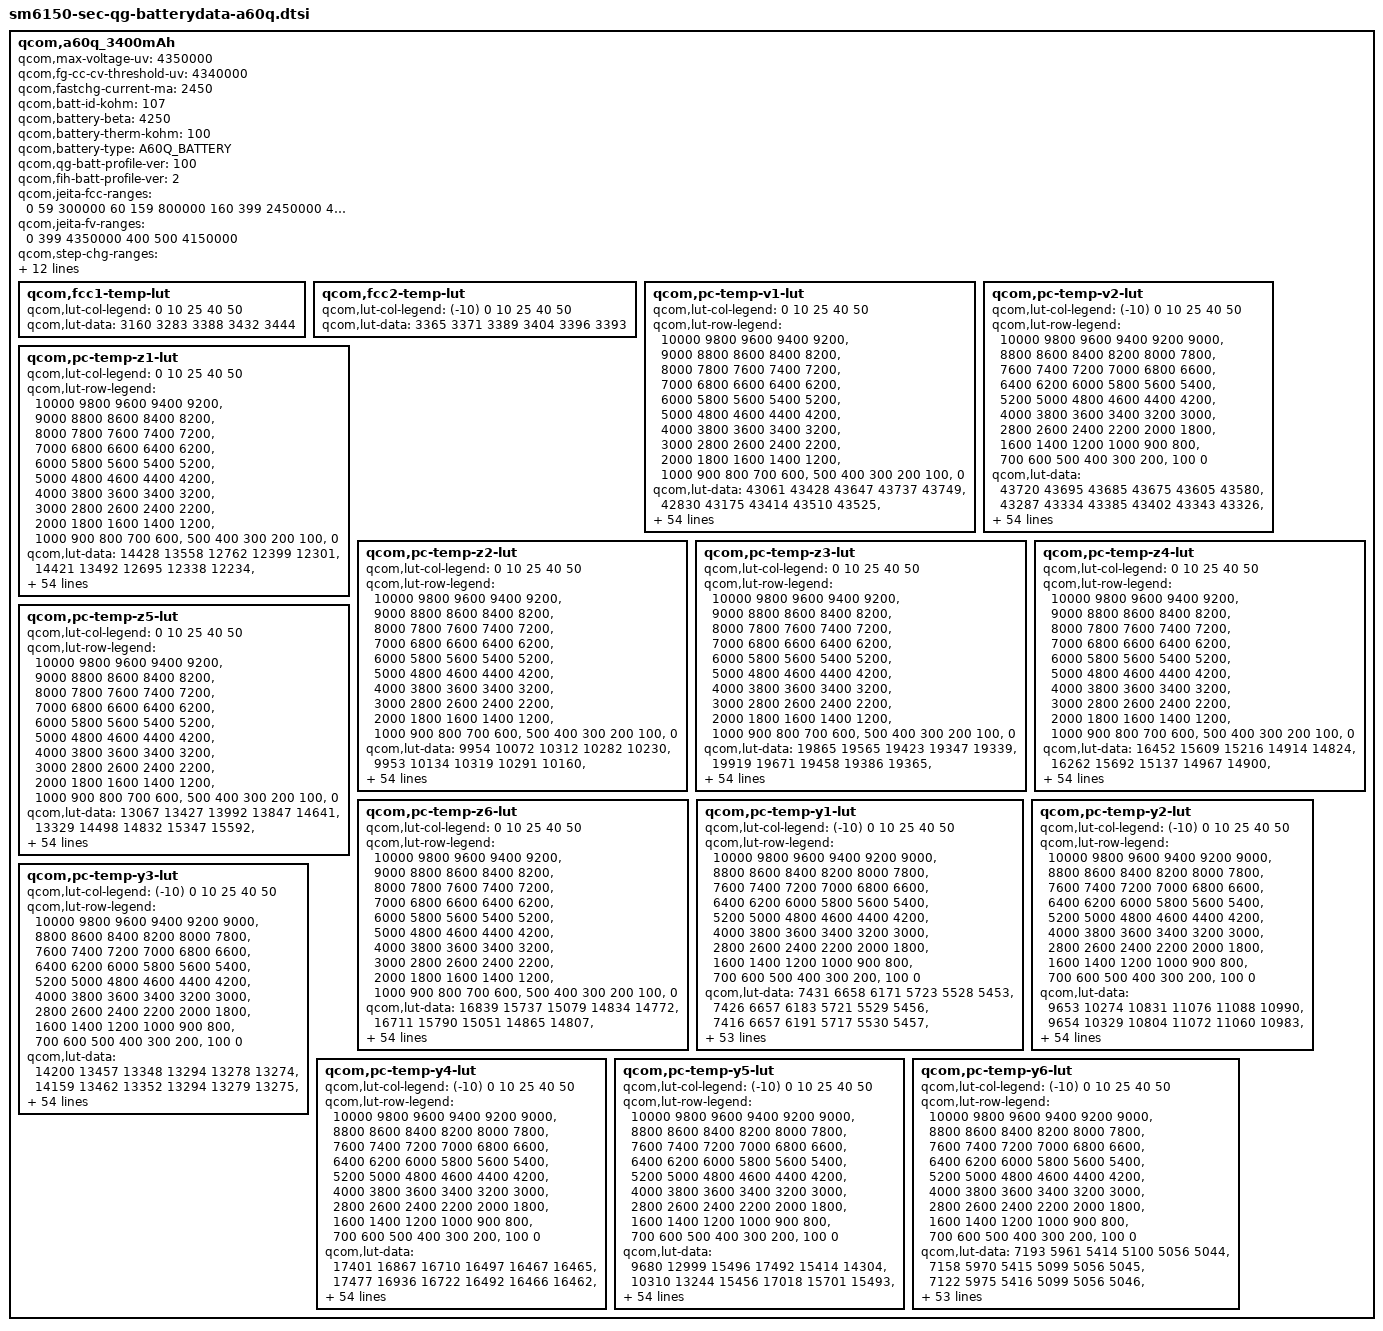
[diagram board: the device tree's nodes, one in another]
/*
 * Copyright (c) 2018, The Linux Foundation. All rights reserved.
 *
 * This program is free software; you can redistribute it and/or modify
 * it under the terms of the GNU General Public License version 2 and
 * only version 2 as published by the Free Software Foundation.
 *
 * This program is distributed in the hope that it will be useful,
 * but WITHOUT ANY WARRANTY; without even the implied warranty of
 * MERCHANTABILITY or FITNESS FOR A PARTICULAR PURPOSE.  See the
 * GNU General Public License for more details.
 */

qcom,a60q_3400mAh {
	 /* 3847662_SS_A60CHN_3400mAh_averaged_MasterSlave_Feb14th2019 */
	qcom,max-voltage-uv = <4350000>;
	qcom,fg-cc-cv-threshold-uv = <4340000>;
	qcom,fastchg-current-ma = <2450>;
	qcom,batt-id-kohm = <107>;
	qcom,battery-beta = <4250>;
	qcom,battery-therm-kohm = <100>;
	qcom,battery-type = "A60Q_BATTERY";
	qcom,qg-batt-profile-ver = <100>;
	qcom,fih-batt-profile-ver = <2>;

	qcom,jeita-fcc-ranges = <0  59   300000
				60  159  800000
				160 399  2450000
				400 490  1200000>;

	qcom,jeita-fv-ranges = <0   399  4350000
				400 500  4150000>;

	qcom,step-chg-ranges = <3400000  4089999  2450000
				4090000  4189999  2450000
				4190000  4350000  2450000>;
	qcom,vbat-avg-based-step-chg;
	qcom,taper-fcc;

	/* COOL = 15 DegC, WARM = 41 DegC */
	qcom,jeita-soft-thresholds = <0x45cd 0x2536>;
	/* COLD = 0 DegC, HOT = 50 DegC */
	qcom,jeita-hard-thresholds = <0x583d 0x1be6>;

	qcom,qg-batt-aging-enable;
	qcom,vfloat-ranges = <0 299 4350000
				300 399 4330000
				400 699 4310000
				700 999 4290000
				1000 9999 4240000>;

	qcom,vbat-rechg-ranges = <0 299 4280000
				300 399 4260000
				400 699 4240000
				700 999 4220000
				1000 9999 4170000>;

	qcom,full-condition-soc-ranges = <0 299 93
				300 399 92
				400 699 91
				700 999 90
				1000 9999 89>;

	qcom,fcc1-temp-lut {
		qcom,lut-col-legend = <0 10 25 40 50>;
		qcom,lut-data = <3160 3283 3388 3432 3444>;
	};

	qcom,fcc2-temp-lut {
		qcom,lut-col-legend = <(-10) 0 10 25 40 50>;
		qcom,lut-data = <3365 3371 3389 3404 3396 3393>;
	};

	qcom,pc-temp-v1-lut {
		qcom,lut-col-legend = <0 10 25 40 50>;
		qcom,lut-row-legend = <10000 9800 9600 9400 9200>,
			<9000 8800 8600 8400 8200>,
			<8000 7800 7600 7400 7200>,
			<7000 6800 6600 6400 6200>,
			<6000 5800 5600 5400 5200>,
			<5000 4800 4600 4400 4200>,
			<4000 3800 3600 3400 3200>,
			<3000 2800 2600 2400 2200>,
			<2000 1800 1600 1400 1200>,
			<1000 900 800 700 600>,
			<500 400 300 200 100>,
			<0>;
		qcom,lut-data = <43061 43428 43647 43737 43749>,
			<42830 43175 43414 43510 43525>,
			<42603 42940 43180 43281 43300>,
			<42379 42713 42944 43050 43076>,
			<42161 42485 42708 42819 42846>,
			<41950 42259 42473 42585 42612>,
			<41745 42036 42242 42353 42381>,
			<41546 41818 42014 42122 42153>,
			<41356 41604 41789 41894 41927>,
			<41171 41397 41565 41668 41700>,
			<40979 41200 41347 41444 41474>,
			<40776 41007 41134 41225 41255>,
			<40572 40808 40927 41010 41041>,
			<40371 40609 40725 40804 40833>,
			<40168 40416 40525 40603 40630>,
			<39990 40228 40336 40410 40434>,
			<39851 40051 40161 40227 40246>,
			<39730 39900 39995 40051 40068>,
			<39608 39771 39838 39883 39897>,
			<39485 39632 39694 39730 39740>,
			<39363 39469 39525 39572 39582>,
			<39243 39292 39269 39362 39384>,
			<39125 39100 39002 39108 39141>,
			<39004 38872 38842 38914 38940>,
			<38870 38691 38734 38783 38799>,
			<38733 38602 38640 38673 38680>,
			<38621 38541 38547 38565 38567>,
			<38531 38486 38461 38464 38464>,
			<38457 38437 38382 38373 38371>,
			<38401 38392 38306 38289 38286>,
			<38359 38346 38240 38214 38210>,
			<38324 38303 38179 38146 38139>,
			<38296 38260 38126 38087 38073>,
			<38272 38221 38079 38032 38012>,
			<38247 38183 38040 37985 37959>,
			<38218 38147 38000 37938 37906>,
			<38184 38116 37963 37888 37844>,
			<38142 38076 37923 37836 37777>,
			<38082 38007 37863 37769 37700>,
			<38007 37908 37775 37682 37611>,
			<37910 37801 37674 37581 37511>,
			<37780 37678 37562 37470 37399>,
			<37633 37537 37433 37342 37270>,
			<37467 37372 37272 37184 37114>,
			<37320 37231 37132 37045 36982>,
			<37220 37141 37045 36963 36902>,
			<37184 37115 37026 36940 36879>,
			<37156 37095 37006 36923 36865>,
			<37125 37075 36985 36905 36844>,
			<37040 37005 36929 36838 36764>,
			<36777 36744 36660 36545 36454>,
			<36319 36294 36218 36102 36009>,
			<35743 35716 35643 35524 35430>,
			<34964 34932 34859 34740 34644>,
			<33706 33677 33623 33504 33402>,
			<30000 30000 30000 30000 30000>;
	};

	qcom,pc-temp-v2-lut {
		qcom,lut-col-legend = <(-10) 0 10 25 40 50>;
		qcom,lut-row-legend = <10000 9800 9600 9400 9200 9000>,
			<8800 8600 8400 8200 8000 7800>,
			<7600 7400 7200 7000 6800 6600>,
			<6400 6200 6000 5800 5600 5400>,
			<5200 5000 4800 4600 4400 4200>,
			<4000 3800 3600 3400 3200 3000>,
			<2800 2600 2400 2200 2000 1800>,
			<1600 1400 1200 1000 900 800>,
			<700 600 500 400 300 200>,
			<100 0>;
		qcom,lut-data = <43720 43695 43685 43675 43605 43580>,
			<43287 43334 43385 43402 43343 43326>,
			<42898 43006 43103 43140 43090 43078>,
			<42558 42716 42839 42890 42846 42838>,
			<42260 42462 42594 42653 42612 42606>,
			<41984 42219 42356 42419 42380 42376>,
			<41693 41979 42120 42185 42149 42146>,
			<41425 41744 41888 41954 41920 41916>,
			<41266 41506 41662 41727 41695 41691>,
			<41184 41257 41439 41503 41472 41469>,
			<41080 41037 41223 41283 41254 41251>,
			<40778 40877 41019 41068 41039 41037>,
			<40317 40739 40821 40856 40829 40828>,
			<39999 40548 40615 40653 40628 40626>,
			<39795 40273 40396 40453 40431 40429>,
			<39610 39998 40190 40262 40243 40239>,
			<39407 39788 40012 40081 40063 40060>,
			<39206 39601 39844 39907 39889 39887>,
			<39017 39403 39649 39739 39722 39720>,
			<38832 39187 39422 39583 39567 39563>,
			<38669 38979 39201 39408 39395 39391>,
			<38538 38792 39002 39173 39166 39166>,
			<38425 38621 38819 38925 38921 38926>,
			<38334 38469 38666 38746 38744 38749>,
			<38260 38331 38536 38608 38610 38615>,
			<38196 38218 38419 38489 38494 38499>,
			<38137 38141 38309 38385 38388 38392>,
			<38082 38081 38207 38292 38292 38295>,
			<38028 38027 38117 38206 38205 38205>,
			<37976 37979 38035 38126 38125 38121>,
			<37924 37934 37965 38052 38053 38046>,
			<37872 37889 37904 37982 37986 37980>,
			<37820 37846 37851 37917 37924 37918>,
			<37766 37800 37807 37855 37859 37851>,
			<37711 37754 37773 37798 37794 37779>,
			<37653 37704 37736 37739 37721 37697>,
			<37591 37647 37691 37673 37628 37591>,
			<37527 37585 37638 37604 37525 37473>,
			<37456 37514 37577 37532 37437 37376>,
			<37375 37431 37507 37457 37363 37299>,
			<37288 37340 37423 37375 37284 37219>,
			<37202 37239 37310 37280 37187 37121>,
			<37117 37127 37174 37171 37074 37008>,
			<37031 37006 37030 37030 36930 36864>,
			<36944 36879 36901 36909 36831 36772>,
			<36850 36765 36819 36855 36793 36737>,
			<36795 36718 36789 36844 36779 36722>,
			<36737 36668 36774 36825 36762 36707>,
			<36662 36614 36738 36796 36728 36674>,
			<36552 36518 36651 36724 36632 36545>,
			<36340 36329 36385 36467 36307 36198>,
			<35966 35912 35899 35990 35821 35704>,
			<35399 35302 35249 35372 35186 35059>,
			<34575 34470 34367 34546 34321 34172>,
			<33218 33139 33060 33268 33044 32883>,
			<30242 27893 27843 27859 27886 27882>;
	};

	qcom,pc-temp-z1-lut {
		qcom,lut-col-legend = <0 10 25 40 50>;
		qcom,lut-row-legend = <10000 9800 9600 9400 9200>,
			<9000 8800 8600 8400 8200>,
			<8000 7800 7600 7400 7200>,
			<7000 6800 6600 6400 6200>,
			<6000 5800 5600 5400 5200>,
			<5000 4800 4600 4400 4200>,
			<4000 3800 3600 3400 3200>,
			<3000 2800 2600 2400 2200>,
			<2000 1800 1600 1400 1200>,
			<1000 900 800 700 600>,
			<500 400 300 200 100>,
			<0>;
		qcom,lut-data = <14428 13558 12762 12399 12301>,
			<14421 13492 12695 12338 12234>,
			<14412 13456 12645 12305 12209>,
			<14374 13430 12618 12285 12194>,
			<14333 13407 12601 12272 12184>,
			<14312 13386 12587 12264 12177>,
			<14283 13373 12572 12259 12175>,
			<14265 13366 12561 12256 12174>,
			<14262 13360 12559 12254 12174>,
			<14263 13352 12558 12253 12174>,
			<14257 13333 12558 12252 12174>,
			<14238 13317 12558 12252 12174>,
			<14212 13314 12558 12252 12175>,
			<14189 13316 12557 12253 12175>,
			<14166 13318 12555 12254 12177>,
			<14151 13312 12554 12255 12179>,
			<14142 13305 12556 12257 12180>,
			<14133 13306 12561 12259 12182>,
			<14131 13314 12566 12261 12183>,
			<14136 13322 12576 12264 12186>,
			<14143 13330 12584 12267 12189>,
			<14149 13338 12587 12271 12191>,
			<14155 13341 12590 12275 12194>,
			<14161 13338 12594 12279 12196>,
			<14171 13336 12599 12285 12201>,
			<14183 13338 12604 12291 12206>,
			<14189 13340 12611 12295 12210>,
			<14186 13344 12618 12300 12214>,
			<14181 13361 12624 12304 12219>,
			<14181 13377 12632 12309 12223>,
			<14184 13376 12639 12313 12227>,
			<14187 13366 12646 12318 12230>,
			<14199 13362 12652 12322 12233>,
			<14220 13366 12656 12327 12237>,
			<14232 13372 12658 12332 12240>,
			<14229 13379 12661 12336 12244>,
			<14225 13392 12667 12341 12248>,
			<14227 13401 12674 12346 12252>,
			<14237 13405 12681 12350 12255>,
			<14247 13408 12686 12355 12259>,
			<14252 13411 12692 12360 12262>,
			<14254 13414 12699 12365 12267>,
			<14265 13422 12706 12370 12272>,
			<14284 13443 12711 12375 12275>,
			<14256 13456 12724 12381 12277>,
			<14259 13442 12725 12387 12280>,
			<14258 13454 12739 12389 12282>,
			<14254 13436 12731 12390 12283>,
			<14257 13450 12735 12394 12287>,
			<14275 13465 12754 12401 12291>,
			<14294 13465 12753 12410 12300>,
			<14301 13482 12767 12424 12311>,
			<14334 13529 12797 12440 12326>,
			<14390 13555 12820 12467 12346>,
			<14390 13555 12820 12467 12346>,
			<14390 13555 12820 12467 12346>;
	};

	qcom,pc-temp-z2-lut {
		qcom,lut-col-legend = <0 10 25 40 50>;
		qcom,lut-row-legend = <10000 9800 9600 9400 9200>,
			<9000 8800 8600 8400 8200>,
			<8000 7800 7600 7400 7200>,
			<7000 6800 6600 6400 6200>,
			<6000 5800 5600 5400 5200>,
			<5000 4800 4600 4400 4200>,
			<4000 3800 3600 3400 3200>,
			<3000 2800 2600 2400 2200>,
			<2000 1800 1600 1400 1200>,
			<1000 900 800 700 600>,
			<500 400 300 200 100>,
			<0>;
		qcom,lut-data = <9954 10072 10312 10282 10230>,
			<9953 10134 10319 10291 10160>,
			<9956 10115 10318 10349 10158>,
			<9970 10083 10309 10380 10158>,
			<9984 10057 10282 10355 10192>,
			<9989 10030 10256 10316 10261>,
			<9992 10010 10229 10286 10269>,
			<9994 9996 10209 10237 10179>,
			<9987 9987 10214 10208 10110>,
			<9972 9985 10240 10205 10115>,
			<9955 9994 10256 10206 10128>,
			<9934 10007 10259 10212 10134>,
			<9912 10020 10259 10218 10135>,
			<9897 10035 10264 10223 10138>,
			<9884 10049 10279 10218 10154>,
			<9877 10063 10288 10212 10176>,
			<9883 10077 10289 10217 10190>,
			<9896 10089 10292 10226 10200>,
			<9902 10100 10296 10232 10212>,
			<9904 10111 10303 10240 10235>,
			<9905 10127 10307 10252 10260>,
			<9908 10142 10294 10262 10275>,
			<9914 10142 10270 10269 10286>,
			<9921 10119 10247 10271 10293>,
			<9932 10101 10221 10287 10297>,
			<9946 10106 10210 10307 10294>,
			<9956 10120 10273 10309 10258>,
			<9961 10130 10356 10306 10169>,
			<9966 10137 10359 10298 10120>,
			<9973 10143 10319 10274 10108>,
			<9985 10147 10293 10243 10101>,
			<9996 10152 10286 10205 10105>,
			<10001 10157 10283 10163 10121>,
			<10004 10164 10290 10155 10142>,
			<10009 10173 10318 10190 10179>,
			<10021 10181 10345 10234 10224>,
			<10035 10187 10361 10262 10266>,
			<10038 10195 10377 10287 10309>,
			<10011 10210 10398 10320 10339>,
			<9989 10227 10431 10369 10364>,
			<10008 10231 10449 10399 10377>,
			<10073 10227 10450 10401 10372>,
			<10540 10226 10452 10401 10362>,
			<12169 10235 10458 10404 10364>,
			<14641 10334 10471 10408 10373>,
			<16171 10363 10490 10444 10394>,
			<16365 10391 10478 10440 10355>,
			<16147 14850 10451 10429 10401>,
			<16310 27487 10482 10466 10460>,
			<16343 12036 10545 10655 10538>,
			<14691 20046 10736 10386 10237>,
			<12946 19041 10620 10287 10156>,
			<10998 18325 10639 10251 10121>,
			<10233 10418 10501 10304 10122>,
			<10233 10418 10501 10304 10122>,
			<10233 10418 10501 10304 10122>;
	};

	qcom,pc-temp-z3-lut {
		qcom,lut-col-legend = <0 10 25 40 50>;
		qcom,lut-row-legend = <10000 9800 9600 9400 9200>,
			<9000 8800 8600 8400 8200>,
			<8000 7800 7600 7400 7200>,
			<7000 6800 6600 6400 6200>,
			<6000 5800 5600 5400 5200>,
			<5000 4800 4600 4400 4200>,
			<4000 3800 3600 3400 3200>,
			<3000 2800 2600 2400 2200>,
			<2000 1800 1600 1400 1200>,
			<1000 900 800 700 600>,
			<500 400 300 200 100>,
			<0>;
		qcom,lut-data = <19865 19565 19423 19347 19339>,
			<19919 19671 19458 19386 19365>,
			<19933 19693 19483 19407 19377>,
			<19932 19704 19495 19417 19386>,
			<19930 19707 19504 19423 19397>,
			<19917 19706 19507 19426 19407>,
			<19878 19705 19501 19425 19407>,
			<19852 19701 19491 19417 19396>,
			<19845 19696 19482 19410 19385>,
			<19841 19688 19472 19404 19382>,
			<19841 19672 19463 19398 19380>,
			<19846 19655 19455 19394 19377>,
			<19852 19644 19449 19390 19371>,
			<19860 19634 19446 19386 19365>,
			<19874 19625 19443 19381 19363>,
			<19882 19617 19440 19375 19361>,
			<19859 19609 19431 19371 19359>,
			<19815 19597 19420 19369 19357>,
			<19795 19583 19418 19366 19355>,
			<19790 19576 19417 19364 19352>,
			<19788 19585 19417 19363 19349>,
			<19789 19599 19429 19362 19346>,
			<19793 19604 19445 19362 19342>,
			<19799 19605 19442 19362 19340>,
			<19810 19605 19421 19358 19353>,
			<19825 19604 19409 19356 19372>,
			<19830 19601 19416 19371 19381>,
			<19826 19598 19429 19400 19389>,
			<19819 19595 19441 19409 19391>,
			<19811 19592 19456 19407 19386>,
			<19803 19592 19463 19404 19377>,
			<19793 19593 19460 19399 19372>,
			<19782 19593 19454 19392 19368>,
			<19768 19592 19449 19385 19363>,
			<19755 19589 19443 19379 19355>,
			<19743 19585 19437 19373 19350>,
			<19730 19579 19433 19369 19349>,
			<19700 19573 19429 19366 19349>,
			<19583 19567 19425 19364 19349>,
			<19479 19561 19421 19363 19351>,
			<19410 19556 19418 19362 19352>,
			<19283 19551 19414 19360 19351>,
			<19261 19544 19411 19358 19348>,
			<19258 19531 19407 19357 19351>,
			<19257 19494 19396 19356 19348>,
			<19257 19480 19391 19345 19336>,
			<19257 19459 19370 19343 19335>,
			<19257 19399 19376 19342 19323>,
			<19257 19267 19371 19328 19318>,
			<19257 19338 19360 19318 19316>,
			<19257 19340 19341 19356 19353>,
			<19257 19310 19353 19358 19356>,
			<19259 19308 19344 19363 19359>,
			<19261 19348 19356 19340 19349>,
			<19261 19348 19356 19340 19349>,
			<19261 19348 19356 19340 19349>;
	};

	qcom,pc-temp-z4-lut {
		qcom,lut-col-legend = <0 10 25 40 50>;
		qcom,lut-row-legend = <10000 9800 9600 9400 9200>,
			<9000 8800 8600 8400 8200>,
			<8000 7800 7600 7400 7200>,
			<7000 6800 6600 6400 6200>,
			<6000 5800 5600 5400 5200>,
			<5000 4800 4600 4400 4200>,
			<4000 3800 3600 3400 3200>,
			<3000 2800 2600 2400 2200>,
			<2000 1800 1600 1400 1200>,
			<1000 900 800 700 600>,
			<500 400 300 200 100>,
			<0>;
		qcom,lut-data = <16452 15609 15216 14914 14824>,
			<16262 15692 15137 14967 14900>,
			<16075 15551 15065 14933 14883>,
			<15880 15338 14999 14894 14859>,
			<15709 15207 14938 14861 14832>,
			<15590 15112 14889 14830 14801>,
			<15498 15036 14851 14805 14781>,
			<15415 14975 14821 14784 14769>,
			<15335 14925 14801 14769 14759>,
			<15261 14885 14785 14759 14749>,
			<15191 14851 14773 14751 14740>,
			<15122 14826 14764 14741 14732>,
			<15061 14810 14755 14731 14726>,
			<15011 14799 14746 14723 14719>,
			<14966 14792 14735 14716 14710>,
			<14933 14790 14727 14709 14700>,
			<14915 14787 14722 14701 14691>,
			<14902 14780 14717 14692 14682>,
			<14887 14765 14711 14686 14677>,
			<14868 14757 14703 14681 14674>,
			<14850 14763 14700 14679 14673>,
			<14838 14780 14777 14715 14698>,
			<14827 14815 14884 14825 14799>,
			<14822 14917 14907 14871 14850>,
			<14831 14992 14910 14866 14830>,
			<14853 14981 14905 14854 14796>,
			<14869 14949 14880 14826 14770>,
			<14880 14919 14840 14773 14745>,
			<14888 14892 14806 14742 14727>,
			<14888 14865 14772 14726 14716>,
			<14875 14842 14749 14715 14708>,
			<14859 14819 14738 14707 14699>,
			<14845 14803 14731 14701 14691>,
			<14830 14792 14727 14699 14687>,
			<14817 14783 14724 14698 14686>,
			<14804 14774 14722 14698 14686>,
			<14794 14764 14723 14701 14690>,
			<14805 14759 14724 14708 14701>,
			<14912 14762 14728 14715 14707>,
			<15008 14765 14738 14723 14710>,
			<15070 14765 14744 14728 14711>,
			<15196 14751 14733 14721 14707>,
			<15208 14742 14722 14712 14700>,
			<15186 14739 14722 14716 14704>,
			<15075 14716 14712 14708 14701>,
			<15065 14703 14690 14694 14684>,
			<15060 14708 14691 14679 14671>,
			<15051 14760 14666 14659 14660>,
			<15038 14899 14657 14651 14643>,
			<15030 14818 14672 14666 14649>,
			<15036 14824 14720 14660 14649>,
			<15063 14874 14712 14662 14650>,
			<15080 14884 14726 14660 14650>,
			<15097 14855 14716 14686 14660>,
			<15097 14855 14716 14686 14660>,
			<15097 14855 14716 14686 14660>;
	};

	qcom,pc-temp-z5-lut {
		qcom,lut-col-legend = <0 10 25 40 50>;
		qcom,lut-row-legend = <10000 9800 9600 9400 9200>,
			<9000 8800 8600 8400 8200>,
			<8000 7800 7600 7400 7200>,
			<7000 6800 6600 6400 6200>,
			<6000 5800 5600 5400 5200>,
			<5000 4800 4600 4400 4200>,
			<4000 3800 3600 3400 3200>,
			<3000 2800 2600 2400 2200>,
			<2000 1800 1600 1400 1200>,
			<1000 900 800 700 600>,
			<500 400 300 200 100>,
			<0>;
		qcom,lut-data = <13067 13427 13992 13847 14641>,
			<13329 14498 14832 15347 15592>,
			<13574 15086 15600 16387 16294>,
			<13857 15561 16316 17047 16947>,
			<14072 16130 17054 17524 18069>,
			<14105 16758 17480 17932 19289>,
			<14049 17407 17674 18197 19505>,
			<14033 18173 17863 18465 18902>,
			<14153 19022 18112 18544 18438>,
			<14382 19750 18439 18530 18725>,
			<14671 20546 18616 18568 19261>,
			<15090 21283 18666 18743 19359>,
			<15661 22107 18796 19235 19189>,
			<16641 23200 19258 19441 19074>,
			<18322 23682 20209 19342 19512>,
			<19311 23384 20674 19419 20456>,
			<18792 23009 20358 19923 21421>,
			<17804 23057 19945 20796 22562>,
			<17481 23176 20085 21699 23616>,
			<18119 23416 21158 22825 24644>,
			<19254 28360 22821 23683 25421>,
			<20583 35581 27600 23373 24554>,
			<22470 37063 32849 21939 20509>,
			<25012 36348 31590 20554 17765>,
			<30035 35305 23116 17480 16724>,
			<36817 33264 18193 14900 16096>,
			<39379 30046 17911 15527 16659>,
			<38823 28073 17879 17704 18450>,
			<37807 26923 18597 19656 19687>,
			<36688 26271 21327 21330 20164>,
			<35230 26616 24176 22864 20619>,
			<33563 28051 26568 24164 21593>,
			<31557 29768 28736 25330 23098>,
			<29202 32299 30325 26315 24104>,
			<27556 34683 31698 27339 24756>,
			<26385 35230 32263 27925 25119>,
			<25313 35377 32059 27439 25094>,
			<24137 35436 31580 26106 24949>,
			<20458 35019 30498 24661 24653>,
			<17201 34065 27687 22800 23551>,
			<15137 33181 25591 21341 22315>,
			<11475 32087 24993 20763 21522>,
			<10929 30409 24414 20289 20926>,
			<10949 27216 22947 19283 20599>,
			<11103 25680 22306 19418 19604>,
			<11073 24198 22849 18159 17942>,
			<11058 19660 18501 18745 18440>,
			<11027 15884 20796 20523 18040>,
			<11020 11272 20876 19051 19444>,
			<11066 12576 18099 16092 17522>,
			<11105 13785 14386 19344 22325>,
			<11066 12143 14736 18683 21663>,
			<11007 11857 13836 19079 21115>,
			<10940 12155 14331 14504 16923>,
			<10940 12155 14331 14504 16923>,
			<10940 12155 14331 14504 16923>;
	};

	qcom,pc-temp-z6-lut {
		qcom,lut-col-legend = <0 10 25 40 50>;
		qcom,lut-row-legend = <10000 9800 9600 9400 9200>,
			<9000 8800 8600 8400 8200>,
			<8000 7800 7600 7400 7200>,
			<7000 6800 6600 6400 6200>,
			<6000 5800 5600 5400 5200>,
			<5000 4800 4600 4400 4200>,
			<4000 3800 3600 3400 3200>,
			<3000 2800 2600 2400 2200>,
			<2000 1800 1600 1400 1200>,
			<1000 900 800 700 600>,
			<500 400 300 200 100>,
			<0>;
		qcom,lut-data = <16839 15737 15079 14834 14772>,
			<16711 15790 15051 14865 14807>,
			<16582 15712 15023 14855 14802>,
			<16447 15592 14997 14843 14796>,
			<16323 15512 14971 14831 14789>,
			<16222 15450 14947 14818 14781>,
			<16134 15397 14925 14805 14772>,
			<16060 15354 14905 14791 14760>,
			<16001 15318 14889 14780 14750>,
			<15949 15285 14876 14772 14744>,
			<15899 15254 14866 14765 14739>,
			<15846 15229 14857 14759 14733>,
			<15800 15210 14850 14752 14727>,
			<15768 15195 14843 14746 14721>,
			<15744 15185 14837 14740 14716>,
			<15722 15178 14832 14734 14711>,
			<15696 15173 14824 14729 14706>,
			<15671 15165 14818 14723 14701>,
			<15657 15155 14815 14720 14697>,
			<15649 15150 14812 14717 14695>,
			<15644 15157 14812 14716 14693>,
			<15644 15173 14853 14732 14703>,
			<15646 15197 14909 14781 14745>,
			<15649 15244 14916 14800 14767>,
			<15660 15276 14909 14797 14765>,
			<15681 15271 14903 14793 14763>,
			<15692 15258 14896 14788 14759>,
			<15695 15246 14889 14782 14753>,
			<15697 15235 14882 14776 14747>,
			<15696 15226 14877 14770 14739>,
			<15688 15217 14871 14764 14732>,
			<15678 15209 14866 14758 14726>,
			<15670 15204 14861 14752 14721>,
			<15661 15200 14857 14747 14716>,
			<15653 15197 14852 14743 14711>,
			<15646 15195 14850 14741 14709>,
			<15639 15192 14850 14741 14710>,
			<15636 15191 14850 14743 14714>,
			<15632 15193 14850 14744 14718>,
			<15630 15197 14854 14748 14721>,
			<15629 15198 14856 14751 14722>,
			<15628 15195 14852 14747 14720>,
			<15630 15194 14847 14743 14717>,
			<15633 15195 14847 14745 14720>,
			<15597 15179 14840 14743 14718>,
			<15599 15170 14829 14732 14705>,
			<15598 15164 14819 14725 14699>,
			<15597 15159 14812 14715 14689>,
			<15597 15156 14807 14705 14678>,
			<15600 15160 14810 14707 14680>,
			<15616 15175 14825 14727 14702>,
			<15643 15192 14831 14732 14707>,
			<15672 15208 14838 14738 14712>,
			<15713 15234 14848 14743 14716>,
			<15713 15234 14848 14743 14716>,
			<15713 15234 14848 14743 14716>;
	};

	qcom,pc-temp-y1-lut {
		qcom,lut-col-legend = <(-10) 0 10 25 40 50>;
		qcom,lut-row-legend = <10000 9800 9600 9400 9200 9000>,
			<8800 8600 8400 8200 8000 7800>,
			<7600 7400 7200 7000 6800 6600>,
			<6400 6200 6000 5800 5600 5400>,
			<5200 5000 4800 4600 4400 4200>,
			<4000 3800 3600 3400 3200 3000>,
			<2800 2600 2400 2200 2000 1800>,
			<1600 1400 1200 1000 900 800>,
			<700 600 500 400 300 200>,
			<100 0>;
		qcom,lut-data = <7431 6658 6171 5723 5528 5453>,
			<7426 6657 6183 5721 5529 5456>,
			<7416 6657 6191 5717 5530 5457>,
			<7406 6657 6195 5714 5530 5458>,
			<7397 6657 6196 5710 5529 5459>,
			<7392 6658 6196 5709 5528 5459>,
			<7391 6665 6193 5708 5525 5459>,
			<7391 6677 6187 5706 5522 5458>,
			<7392 6679 6186 5706 5521 5457>,
			<7400 6672 6185 5703 5520 5456>,
			<7409 6667 6185 5702 5520 5456>,
			<7416 6671 6187 5702 5520 5456>,
			<7422 6679 6191 5703 5521 5457>,
			<7423 6688 6191 5703 5521 5457>,
			<7422 6703 6186 5702 5521 5457>,
			<7419 6714 6182 5701 5522 5458>,
			<7412 6710 6186 5702 5523 5460>,
			<7400 6702 6193 5703 5524 5463>,
			<7397 6701 6196 5704 5526 5464>,
			<7407 6714 6197 5706 5529 5464>,
			<7415 6726 6199 5709 5531 5464>,
			<7411 6726 6201 5711 5531 5466>,
			<7399 6720 6203 5715 5531 5468>,
			<7395 6716 6203 5717 5532 5470>,
			<7405 6703 6199 5720 5535 5471>,
			<7416 6691 6196 5723 5539 5472>,
			<7415 6694 6198 5727 5541 5474>,
			<7410 6703 6200 5732 5543 5477>,
			<7408 6706 6203 5736 5545 5479>,
			<7408 6701 6207 5740 5548 5481>,
			<7408 6695 6210 5744 5550 5483>,
			<7404 6699 6214 5750 5553 5486>,
			<7392 6708 6220 5756 5556 5489>,
			<7387 6712 6222 5759 5558 5492>,
			<7397 6707 6220 5762 5561 5494>,
			<7409 6701 6220 5764 5564 5495>,
			<7410 6703 6221 5770 5568 5497>,
			<7408 6711 6223 5776 5572 5498>,
			<7405 6715 6227 5779 5575 5500>,
			<7410 6710 6236 5780 5577 5504>,
			<7417 6705 6248 5783 5579 5508>,
			<7416 6704 6258 5786 5581 5508>,
			<7411 6703 6266 5790 5583 5509>,
			<7405 6705 6254 5794 5585 5512>,
			<7395 6715 6254 5802 5588 5515>,
			<7422 6735 6264 5804 5594 5519>,
			<7428 6743 6263 5807 5593 5519>,
			<7431 6777 6256 5806 5594 5519>,
			<7432 6768 6271 5807 5595 5520>,
			<7423 6743 6263 5811 5596 5522>,
			<7456 6767 6271 5817 5600 5526>,
			<7451 6769 6295 5823 5609 5534>,
			<7489 6795 6327 5841 5622 5544>,
			<7520 6834 6334 5866 5638 5558>,
			<7520 6834 6334 5866 5638 5558>,
			<7520 6834 6334 5866 5638 5558>;
	};

	qcom,pc-temp-y2-lut {
		qcom,lut-col-legend = <(-10) 0 10 25 40 50>;
		qcom,lut-row-legend = <10000 9800 9600 9400 9200 9000>,
			<8800 8600 8400 8200 8000 7800>,
			<7600 7400 7200 7000 6800 6600>,
			<6400 6200 6000 5800 5600 5400>,
			<5200 5000 4800 4600 4400 4200>,
			<4000 3800 3600 3400 3200 3000>,
			<2800 2600 2400 2200 2000 1800>,
			<1600 1400 1200 1000 900 800>,
			<700 600 500 400 300 200>,
			<100 0>;
		qcom,lut-data = <9653 10274 10831 11076 11088 10990>,
			<9654 10329 10804 11072 11060 10983>,
			<9655 10374 10778 11058 11019 10963>,
			<9656 10407 10754 11037 10976 10936>,
			<9656 10428 10731 11014 10940 10911>,
			<9657 10436 10711 10993 10919 10894>,
			<9658 10424 10691 10967 10912 10879>,
			<9658 10403 10674 10940 10907 10861>,
			<9659 10409 10667 10930 10901 10850>,
			<9660 10483 10665 10916 10893 10835>,
			<9660 10539 10664 10908 10889 10826>,
			<9660 10526 10669 10913 10887 10834>,
			<9659 10501 10679 10921 10881 10849>,
			<9658 10502 10697 10918 10871 10852>,
			<9658 10556 10740 10902 10858 10849>,
			<9658 10600 10779 10895 10847 10841>,
			<9658 10603 10806 10915 10842 10823>,
			<9658 10604 10829 10951 10843 10803>,
			<9658 10605 10829 11001 10873 10813>,
			<9657 10607 10808 11079 10997 10896>,
			<9657 10612 10792 11119 11085 10959>,
			<9657 10620 10800 11080 11080 10957>,
			<9657 10632 10819 11022 11057 10945>,
			<9656 10603 10839 11017 11049 10955>,
			<9656 10229 10867 11043 11032 10977>,
			<9656 9865 10892 11073 11020 11002>,
			<9656 9812 10907 11107 11055 11027>,
			<9655 9789 10920 11139 11114 11053>,
			<9655 9773 10929 11153 11133 11076>,
			<9654 9748 10938 11161 11130 11103>,
			<9654 9722 10943 11165 11126 11122>,
			<9654 9703 10946 11165 11139 11127>,
			<9654 9686 10947 11162 11165 11130>,
			<9653 9677 10942 11161 11181 11138>,
			<9653 9672 10919 11161 11194 11155>,
			<9653 9669 10887 11161 11199 11168>,
			<9653 9665 10855 11159 11177 11166>,
			<9653 9662 10817 11158 11141 11157>,
			<9653 9660 10772 11164 11134 11144>,
			<9653 9659 10715 11176 11138 11109>,
			<9653 9657 10644 11184 11141 11082>,
			<9653 9656 10423 11178 11146 11072>,
			<9653 9655 10149 11167 11154 11067>,
			<9653 9654 10177 11146 11160 11111>,
			<9652 9654 10153 11103 11128 11096>,
			<9652 9653 10002 11102 11067 10951>,
			<9652 9653 9979 11030 11029 10878>,
			<9652 9653 10207 11080 10996 10853>,
			<9652 9653 10259 11075 10984 10835>,
			<9652 9653 10245 11009 10972 10860>,
			<9652 9652 9962 10995 10952 10833>,
			<9652 9652 9758 10943 10907 10760>,
			<9651 9651 9692 10898 10822 10724>,
			<9651 9651 9671 10790 10694 10598>,
			<9651 9651 9671 10790 10694 10598>,
			<9651 9651 9671 10790 10694 10598>;
	};

	qcom,pc-temp-y3-lut {
		qcom,lut-col-legend = <(-10) 0 10 25 40 50>;
		qcom,lut-row-legend = <10000 9800 9600 9400 9200 9000>,
			<8800 8600 8400 8200 8000 7800>,
			<7600 7400 7200 7000 6800 6600>,
			<6400 6200 6000 5800 5600 5400>,
			<5200 5000 4800 4600 4400 4200>,
			<4000 3800 3600 3400 3200 3000>,
			<2800 2600 2400 2200 2000 1800>,
			<1600 1400 1200 1000 900 800>,
			<700 600 500 400 300 200>,
			<100 0>;
		qcom,lut-data = <14200 13457 13348 13294 13278 13274>,
			<14159 13462 13352 13294 13279 13275>,
			<14114 13471 13355 13295 13280 13277>,
			<14065 13480 13359 13295 13281 13278>,
			<14013 13488 13362 13295 13281 13279>,
			<13959 13492 13365 13295 13282 13280>,
			<13889 13494 13368 13295 13282 13279>,
			<13821 13494 13370 13295 13282 13279>,
			<13805 13493 13373 13295 13282 13279>,
			<13812 13481 13375 13295 13283 13280>,
			<13816 13470 13377 13295 13283 13281>,
			<13790 13465 13378 13296 13283 13281>,
			<13738 13461 13379 13297 13283 13281>,
			<13703 13457 13379 13298 13283 13281>,
			<13675 13453 13374 13302 13286 13281>,
			<13651 13449 13369 13305 13288 13280>,
			<13634 13440 13367 13306 13289 13282>,
			<13619 13428 13365 13308 13289 13284>,
			<13614 13417 13362 13309 13291 13286>,
			<13612 13407 13353 13310 13294 13289>,
			<13611 13398 13344 13311 13297 13291>,
			<13613 13390 13339 13306 13292 13286>,
			<13621 13384 13334 13297 13283 13279>,
			<13632 13369 13332 13292 13280 13278>,
			<13658 13314 13331 13287 13280 13278>,
			<13692 13268 13330 13285 13279 13278>,
			<13728 13267 13327 13287 13279 13278>,
			<13768 13269 13322 13290 13278 13277>,
			<13812 13271 13321 13292 13278 13277>,
			<13859 13276 13321 13293 13279 13276>,
			<13911 13283 13322 13293 13280 13276>,
			<13970 13297 13321 13292 13280 13276>,
			<14036 13323 13320 13292 13280 13277>,
			<14103 13350 13320 13292 13280 13277>,
			<14172 13376 13325 13292 13281 13277>,
			<14242 13405 13329 13292 13281 13277>,
			<14315 13441 13331 13292 13280 13277>,
			<14391 13484 13332 13291 13278 13276>,
			<14463 13534 13334 13290 13278 13276>,
			<14530 13593 13339 13287 13278 13276>,
			<14594 13660 13344 13285 13278 13276>,
			<14661 13737 13342 13289 13278 13277>,
			<14730 13828 13339 13292 13278 13277>,
			<14805 13933 13345 13290 13278 13276>,
			<14887 14049 13353 13290 13278 13276>,
			<14972 14129 13358 13286 13281 13279>,
			<14905 14096 13362 13291 13282 13280>,
			<15003 14165 13382 13292 13286 13286>,
			<15097 14251 13398 13298 13289 13288>,
			<15205 14326 13412 13302 13291 13286>,
			<15323 14409 13412 13298 13286 13284>,
			<15479 14491 13427 13299 13286 13285>,
			<15697 14698 13476 13303 13288 13287>,
			<16155 14978 13569 13311 13295 13291>,
			<16155 14978 13569 13311 13295 13291>,
			<16155 14978 13569 13311 13295 13291>;
	};

	qcom,pc-temp-y4-lut {
		qcom,lut-col-legend = <(-10) 0 10 25 40 50>;
		qcom,lut-row-legend = <10000 9800 9600 9400 9200 9000>,
			<8800 8600 8400 8200 8000 7800>,
			<7600 7400 7200 7000 6800 6600>,
			<6400 6200 6000 5800 5600 5400>,
			<5200 5000 4800 4600 4400 4200>,
			<4000 3800 3600 3400 3200 3000>,
			<2800 2600 2400 2200 2000 1800>,
			<1600 1400 1200 1000 900 800>,
			<700 600 500 400 300 200>,
			<100 0>;
		qcom,lut-data = <17401 16867 16710 16497 16467 16465>,
			<17477 16936 16722 16492 16466 16462>,
			<17554 17025 16745 16491 16466 16461>,
			<17627 17117 16772 16491 16466 16460>,
			<17692 17194 16794 16493 16466 16459>,
			<17742 17238 16804 16496 16466 16459>,
			<17774 17253 16803 16501 16468 16460>,
			<17802 17263 16802 16507 16471 16463>,
			<17875 17275 16802 16514 16475 16465>,
			<18089 17290 16806 16521 16479 16468>,
			<18240 17312 16814 16529 16485 16471>,
			<18017 17412 16832 16537 16491 16475>,
			<17569 17564 16863 16547 16499 16481>,
			<17403 17578 16889 16557 16506 16488>,
			<17373 17381 16915 16567 16512 16496>,
			<17346 17207 16939 16581 16519 16504>,
			<17293 17180 16968 16602 16531 16513>,
			<17222 17167 16995 16630 16547 16522>,
			<17150 17134 16988 16668 16571 16539>,
			<17065 17035 16898 16721 16613 16570>,
			<16999 16923 16796 16748 16636 16589>,
			<16975 16828 16718 16666 16588 16555>,
			<16959 16742 16650 16542 16507 16495>,
			<16950 16723 16617 16507 16481 16473>,
			<16943 16764 16599 16496 16472 16466>,
			<16939 16805 16588 16492 16468 16463>,
			<16940 16812 16580 16493 16470 16464>,
			<16944 16813 16574 16493 16474 16467>,
			<16948 16813 16566 16495 16480 16471>,
			<16955 16819 16555 16503 16488 16479>,
			<16966 16823 16548 16511 16497 16488>,
			<16975 16821 16547 16521 16511 16501>,
			<16985 16816 16547 16530 16525 16515>,
			<16995 16815 16550 16534 16529 16519>,
			<17005 16827 16565 16536 16530 16519>,
			<17012 16843 16584 16537 16531 16518>,
			<17014 16854 16602 16523 16512 16502>,
			<17014 16864 16622 16503 16482 16477>,
			<17014 16868 16642 16496 16476 16472>,
			<17014 16867 16662 16493 16477 16472>,
			<17013 16865 16680 16491 16478 16473>,
			<17016 16866 16696 16491 16477 16472>,
			<17026 16871 16710 16491 16474 16469>,
			<17049 16885 16689 16495 16466 16457>,
			<17093 16923 16680 16488 16463 16454>,
			<17131 16972 16702 16496 16469 16464>,
			<17088 16968 16728 16508 16482 16480>,
			<17122 17047 16770 16525 16502 16507>,
			<17169 17125 16834 16550 16534 16548>,
			<17216 17205 16917 16576 16543 16518>,
			<17210 17253 16892 16537 16474 16466>,
			<17162 17212 16868 16516 16475 16466>,
			<17145 17209 16907 16535 16486 16476>,
			<17248 17260 16988 16594 16536 16524>,
			<17248 17260 16988 16594 16536 16524>,
			<17248 17260 16988 16594 16536 16524>;
	};

	qcom,pc-temp-y5-lut {
		qcom,lut-col-legend = <(-10) 0 10 25 40 50>;
		qcom,lut-row-legend = <10000 9800 9600 9400 9200 9000>,
			<8800 8600 8400 8200 8000 7800>,
			<7600 7400 7200 7000 6800 6600>,
			<6400 6200 6000 5800 5600 5400>,
			<5200 5000 4800 4600 4400 4200>,
			<4000 3800 3600 3400 3200 3000>,
			<2800 2600 2400 2200 2000 1800>,
			<1600 1400 1200 1000 900 800>,
			<700 600 500 400 300 200>,
			<100 0>;
		qcom,lut-data = <9680 12999 15496 17492 15414 14304>,
			<10310 13244 15456 17018 15701 15493>,
			<10826 13594 15413 16531 15770 16216>,
			<11213 13970 15368 16034 15700 16589>,
			<11458 14288 15326 15533 15570 16728>,
			<11549 14467 15289 15030 15456 16748>,
			<11412 14538 15262 14485 15095 16244>,
			<11175 14586 15232 13960 14511 15342>,
			<11354 14441 15159 13582 14161 14897>,
			<12996 13412 14949 13283 13893 14687>,
			<14260 12639 14670 13049 13632 14472>,
			<13823 13406 14208 12837 13280 14161>,
			<12899 14896 13706 12681 12950 13812>,
			<12496 15438 13635 12703 12942 13467>,
			<12353 15557 13847 12931 13215 13076>,
			<12274 15657 14173 13086 13396 12874>,
			<12221 15808 14745 13086 13264 12960>,
			<12128 15993 15508 13076 13052 13165>,
			<11996 16178 16033 13293 13129 13434>,
			<11726 16388 16439 14341 13860 13929>,
			<11416 16551 16700 15345 14623 14410>,
			<11133 16633 16771 16043 15173 14877>,
			<10862 16689 16773 16560 15643 15480>,
			<10783 16447 16886 16344 15850 16126>,
			<10801 13538 17311 14995 15982 16975>,
			<10827 10786 17610 14185 16039 17451>,
			<10861 10575 17065 14957 15751 17096>,
			<10913 10600 16076 16164 15270 16333>,
			<10933 10621 15915 16664 15156 15658>,
			<10941 10647 16523 16982 15299 14933>,
			<10962 10713 16987 17114 15410 14541>,
			<11004 10873 16698 16969 15415 14625>,
			<11066 11144 16153 16763 15458 14835>,
			<11129 11320 16116 16860 15690 15153>,
			<11186 11447 16905 17454 16466 15902>,
			<11247 11561 17524 17885 16973 16439>,
			<11335 11644 17234 18113 16865 16493>,
			<11451 11725 16634 18265 16607 16475>,
			<11498 11760 16431 17724 16279 16395>,
			<11372 11769 16510 15835 15756 16201>,
			<11196 11773 16596 14790 15427 16030>,
			<11128 11764 15721 16224 15411 15908>,
			<11095 11735 14440 17414 15420 15834>,
			<11087 11687 14222 16421 15596 16926>,
			<11096 11608 14070 16358 15833 16944>,
			<11244 11579 13408 14300 15343 15611>,
			<11211 11624 13202 15212 14742 14931>,
			<11397 11595 14536 14258 15472 15737>,
			<11519 12028 14834 14609 15205 15333>,
			<11691 12370 14872 15108 15089 15033>,
			<11700 12651 13771 14977 16281 16723>,
			<11512 12051 12479 16195 15680 16929>,
			<11199 11447 11736 16068 16132 17247>,
			<10820 11262 11673 17274 18370 18447>,
			<10820 11262 11673 17274 18370 18447>,
			<10820 11262 11673 17274 18370 18447>;
	};

	qcom,pc-temp-y6-lut {
		qcom,lut-col-legend = <(-10) 0 10 25 40 50>;
		qcom,lut-row-legend = <10000 9800 9600 9400 9200 9000>,
			<8800 8600 8400 8200 8000 7800>,
			<7600 7400 7200 7000 6800 6600>,
			<6400 6200 6000 5800 5600 5400>,
			<5200 5000 4800 4600 4400 4200>,
			<4000 3800 3600 3400 3200 3000>,
			<2800 2600 2400 2200 2000 1800>,
			<1600 1400 1200 1000 900 800>,
			<700 600 500 400 300 200>,
			<100 0>;
		qcom,lut-data = <7193 5961 5414 5100 5056 5044>,
			<7158 5970 5415 5099 5056 5045>,
			<7122 5975 5416 5099 5056 5046>,
			<7084 5977 5416 5099 5057 5046>,
			<7047 5978 5416 5099 5057 5047>,
			<7008 5978 5416 5100 5058 5047>,
			<6959 5975 5413 5101 5059 5048>,
			<6914 5966 5407 5102 5060 5048>,
			<6911 5956 5404 5103 5061 5049>,
			<6960 5941 5402 5105 5062 5050>,
			<6997 5931 5401 5108 5064 5052>,
			<6922 5949 5403 5110 5066 5054>,
			<6767 5983 5409 5113 5068 5055>,
			<6696 5985 5411 5117 5071 5057>,
			<6671 5933 5413 5122 5074 5059>,
			<6651 5882 5415 5128 5078 5062>,
			<6629 5866 5419 5136 5082 5065>,
			<6607 5857 5426 5145 5087 5070>,
			<6587 5840 5422 5156 5095 5076>,
			<6565 5808 5390 5172 5109 5087>,
			<6552 5775 5354 5181 5118 5094>,
			<6554 5752 5328 5154 5100 5081>,
			<6561 5733 5306 5112 5071 5058>,
			<6571 5721 5298 5099 5061 5051>,
			<6591 5712 5294 5093 5058 5049>,
			<6618 5707 5291 5091 5057 5048>,
			<6647 5714 5289 5092 5057 5048>,
			<6682 5735 5288 5095 5058 5049>,
			<6719 5758 5287 5098 5060 5050>,
			<6760 5783 5288 5101 5063 5052>,
			<6804 5812 5289 5104 5067 5054>,
			<6851 5846 5291 5107 5071 5058>,
			<6902 5887 5296 5110 5075 5063>,
			<6955 5932 5302 5112 5077 5065>,
			<7009 5980 5315 5114 5078 5065>,
			<7065 6032 5331 5115 5078 5065>,
			<7120 6088 5347 5112 5073 5061>,
			<7176 6148 5364 5106 5064 5053>,
			<7230 6211 5384 5104 5062 5051>,
			<7280 6278 5410 5102 5062 5052>,
			<7329 6348 5436 5101 5062 5053>,
			<7382 6425 5461 5104 5063 5053>,
			<7438 6508 5486 5107 5063 5052>,
			<7503 6604 5516 5109 5060 5049>,
			<7578 6710 5559 5107 5060 5048>,
			<7655 6791 5580 5108 5064 5054>,
			<7602 6769 5597 5116 5069 5059>,
			<7683 6845 5646 5122 5078 5071>,
			<7768 6937 5696 5133 5090 5085>,
			<7868 7020 5751 5145 5093 5075>,
			<7962 7106 5760 5132 5070 5059>,
			<8076 7167 5794 5128 5072 5061>,
			<8251 7338 5898 5140 5078 5067>,
			<8678 7577 6055 5167 5099 5085>,
			<8678 7577 6055 5167 5099 5085>,
			<8678 7577 6055 5167 5099 5085>;
	};
};
